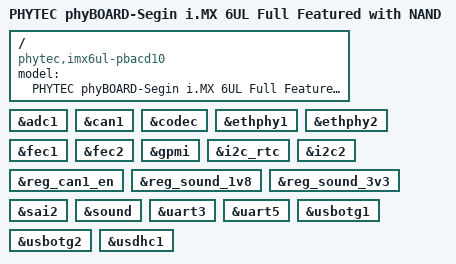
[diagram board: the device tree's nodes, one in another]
// SPDX-License-Identifier: (GPL-2.0+ OR MIT)
/*
 * Copyright (C) 2016 PHYTEC Messtechnik GmbH
 * Author: Christian Hemp <c.hemp@phytec.de>
 */
/dts-v1/;

#include "imx6ul.dtsi"
#include "imx6ul-phytec-phycore-som.dtsi"

/* ADC---CAM--uart5 */
/* #include "imx6ul-phytec-segin.dtsi" */
#include "imx6ul-embdes-segin.dtsi" 

/*#include "imx6ul-phytec-segin-peb-eval-01.dtsi" */
#include "imx6ul-embdes-segin-peb-eval-01.dtsi"

#include "imx6ul-phytec-peb-wlbt-01.dtsi"

/*#include "imx6ul-phytec-segin-peb-av-02.dtsi" */
#include "imx6ul-phytec-segin-peb-av-02-embdes.dtsi"

/*#include "imx6ul-embdes-segin-gpio.dtsi" */
#include "imx6ul-embdes-segin-adc.dtsi"     
/*#include "imx6ul-embdes-segin-wakeup.dtsi" */
/*#include "imx6ul-embdes-segin-uart.dtsi" */


/ {
	model = "PHYTEC phyBOARD-Segin i.MX 6UL Full Featured with NAND";
	compatible = "phytec,imx6ul-pbacd10", "phytec,imx6ul-pcl063","fsl,imx6ul";
};


&adc1 {
	status = "okay";
};

&can1 {
	status = "okay";
};

&codec {
	status = "okay";
};
/*
&csi {
	status = "okay";
};
*/
&ethphy1 {
	status = "okay";
};

&ethphy2 {
	status = "okay";
 };

&fec1 {
	status = "okay";
};

&fec2 {
	status = "okay";
};

&gpmi {
	status = "okay";
};

&i2c_rtc {
	status = "okay";
};

&i2c2 {
        status = "okay";
};

&reg_can1_en {
	status = "okay";
};

&reg_sound_1v8 {
	status = "okay";
};

&reg_sound_3v3 {
	status = "okay";
};

&sai2 {
	status = "okay";
};

&sound {
	status = "okay";
};

&uart3 {
        status = "okay";
};


&uart5 {
	status = "okay";
};


&usbotg1 {
	status = "okay";
};

&usbotg2 {
	status = "okay";
};

&usdhc1 {
	status = "okay";
};

